VERSION ""

NS_ :

BS_:

BU_:

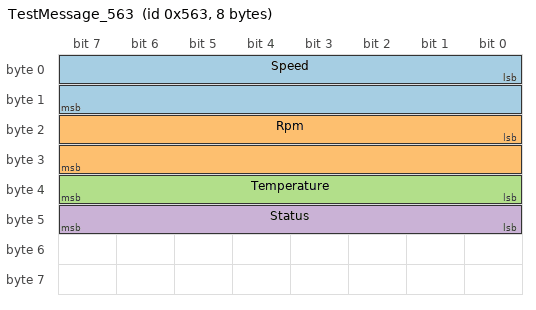
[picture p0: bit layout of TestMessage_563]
BO_ 1379 TestMessage_563: 8 Vector__XXX
 SG_ Speed : 0|16@1+ (0.1,0) [0|6553.5] "km/h" Vector__XXX
 SG_ Rpm : 16|16@1+ (1,0) [0|65535] "rpm" Vector__XXX
 SG_ Temperature : 32|8@1- (1,40) [-40|215] "C" Vector__XXX
 SG_ Status : 40|8@1+ (1,0) [0|255] "" Vector__XXX

VAL_ 1379 Status 1 "Active" 0 "Inactive" ;
